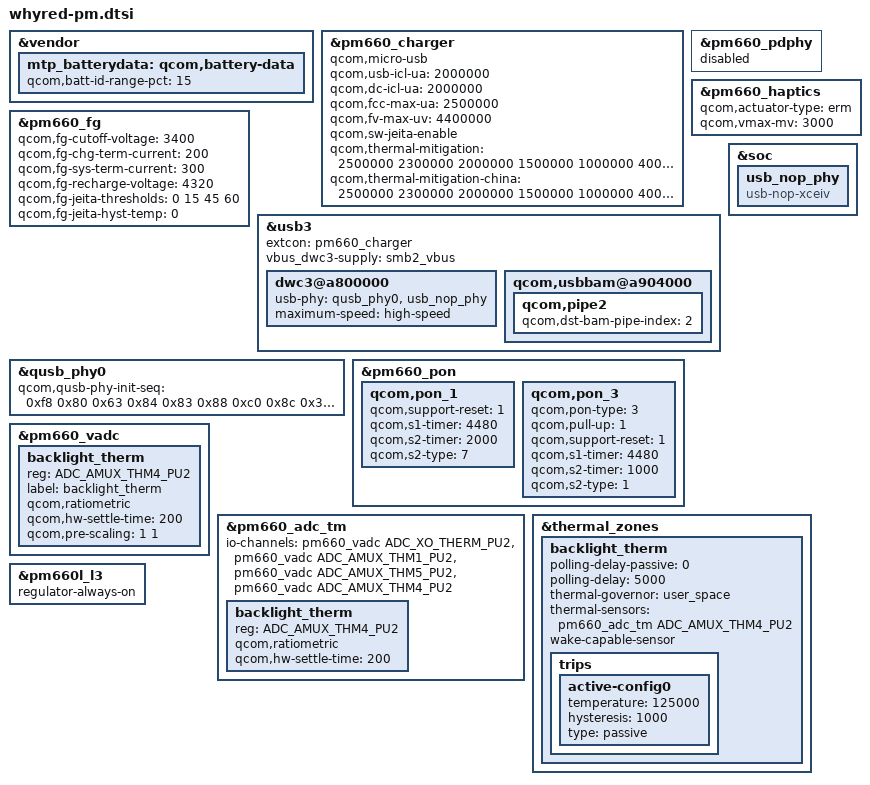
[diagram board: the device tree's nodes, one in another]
/* Copyright (c) 2017, The Linux Foundation. All rights reserved.
 * Copyright (C) 2019 XiaoMi, Inc.
 *
 * This program is free software; you can redistribute it and/or modify
 * it under the terms of the GNU General Public License version 2 and
 * only version 2 as published by the Free Software Foundation.
 *
 * This program is distributed in the hope that it will be useful,
 * but WITHOUT ANY WARRANTY; without even the implied warranty of
 * MERCHANTABILITY or FITNESS FOR A PARTICULAR PURPOSE.  See the
 * GNU General Public License for more details.
*/

&vendor {
	mtp_batterydata: qcom,battery-data {
		qcom,batt-id-range-pct = <15>;
		#include "batterydata/fg-gen3-batterydata-l6650sun-4000mah.dtsi"
		#include "batterydata/fg-gen3-batterydata-l6650cos-4000mah.dtsi"
		#include "batterydata/fg-gen3-batterydata-l6650desay-4000mah.dtsi"
		/delete-node/ qcom,itech_3000mah;
		/delete-node/ qcom,ascent_3450mah;
	};
};

&pm660_charger {
	qcom,micro-usb;
	qcom,usb-icl-ua = <2000000>;
	qcom,dc-icl-ua = <2000000>;
	qcom,fcc-max-ua = <2500000>;
	qcom,fv-max-uv  = <4400000>;
	qcom,sw-jeita-enable;
	qcom,thermal-mitigation
			= <2500000 2300000 2000000 1500000 1000000 400000 200000>;
	qcom,thermal-mitigation-china
			= <2500000 2300000 2000000 1500000 1000000 400000 200000>;
};

&pm660_pdphy {
	status = "disabled";
};

&pm660_fg {
	qcom,fg-cutoff-voltage = <3400>;
	qcom,fg-chg-term-current = <200>;
	qcom,fg-sys-term-current = <300>;
	qcom,fg-recharge-voltage = <4320>;
	qcom,fg-jeita-thresholds = <0 15 45 60>;
	qcom,fg-jeita-hyst-temp = <0>;
};

&pm660_haptics {
	qcom,actuator-type = "erm";
	qcom,vmax-mv = <3000>;
};

&usb3 {
	extcon = <&pm660_charger>;
	vbus_dwc3-supply = <&smb2_vbus>;

	dwc3@a800000 {
		usb-phy = <&qusb_phy0>, <&usb_nop_phy>;
		maximum-speed = "high-speed";
	};

	qcom,usbbam@a904000 {
		qcom,pipe2 {
			qcom,dst-bam-pipe-index = <2>;
		};
	};
};

&qusb_phy0 {
	qcom,qusb-phy-init-seq = <0xf8 0x80
			0x63 0x84
			0x83 0x88
			0xc0 0x8c
			0x30 0x08
			0x79 0x0c
			0x21 0x10
			0x14 0x9c
			0x9f 0x1c
			0x00 0x18>;
};

&soc {
	usb_nop_phy: usb_nop_phy {
		compatible = "usb-nop-xceiv";
	};
};

&pm660_pon {
	qcom,pon_1 {
		qcom,support-reset = <1>;
		qcom,s1-timer = <4480>;
		qcom,s2-timer = <2000>;
		qcom,s2-type = <7>;
	};

	qcom,pon_3 {
		qcom,pon-type = <3>;
		qcom,pull-up = <1>;
		qcom,support-reset = <1>;
		qcom,s1-timer = <4480>;
		qcom,s2-timer = <1000>;
		qcom,s2-type = <1>;
	};
};

&pm660_vadc {
	backlight_therm {
		reg = <ADC_AMUX_THM4_PU2>;
		label = "backlight_therm";
		qcom,ratiometric;
		qcom,hw-settle-time = <200>;
		qcom,pre-scaling = <1 1>;
	};
};

&pm660_adc_tm {
	io-channels = <&pm660_vadc ADC_XO_THERM_PU2>,
			<&pm660_vadc ADC_AMUX_THM1_PU2>,
			<&pm660_vadc ADC_AMUX_THM5_PU2>,
			<&pm660_vadc ADC_AMUX_THM4_PU2>;

	backlight_therm {
		reg = <ADC_AMUX_THM4_PU2>;
		qcom,ratiometric;
		qcom,hw-settle-time = <200>;
	};
};

&thermal_zones {
	backlight_therm {
		polling-delay-passive = <0>;
		polling-delay = <5000>;
		thermal-governor = "user_space";
		thermal-sensors = <&pm660_adc_tm ADC_AMUX_THM4_PU2>;
		wake-capable-sensor;
		trips {
			active-config0 {
				temperature = <125000>;
				hysteresis = <1000>;
				type = "passive";
			};
		};
	};
};

&pm660l_l3 {
	regulator-always-on;
};
